# STM32H7P4 register map
File version: 2.0.0
CPU: CM7 r1p2, little endian, MPU, FPU, 4 interrupt priority bits
Registers are 32-bit, read-write, reset 0x0 unless marked. A register's access mark holds for its fields unless they carry their own. Offsets are from the block's base; [hi:lo] are bit positions; {n}, {i} and the like mark numbered series; 'fields as' and 'values as' point back to an identical list.

## HPDMA1 — HPDMA register block
Base 0x52000000
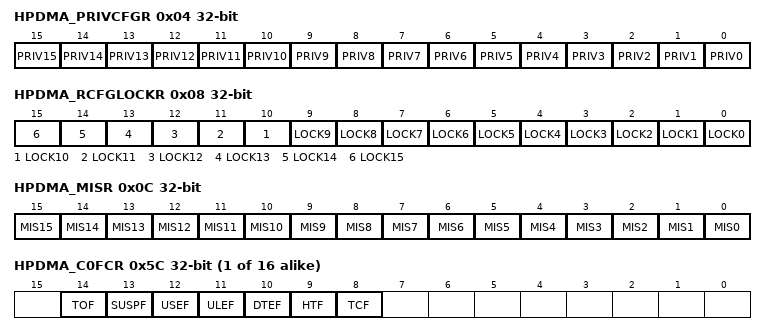
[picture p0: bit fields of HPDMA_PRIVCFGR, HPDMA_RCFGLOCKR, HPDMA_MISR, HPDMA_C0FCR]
0x04 HPDMA_PRIVCFGR — HPDMA privileged configuration register
  [all] fields
    0=Unprivileged; 1=Privileged
  [n] PRIV{n} (n=0..15) — Privileged state of channel x
0x08 HPDMA_RCFGLOCKR — HPDMA configuration lock register
  [all] fields
    0=privilege configuration of the channel x is writable; 1=privilege configuration of the channel x is not writable
  [n] LOCK{n} (n=0..15) — Lock of the configuration of HPDMA_PRIVCFGR.PRIVx until a global HPDMA reset
0x0C HPDMA_MISR ro — HPDMA masked interrupt status register
  [all] fields
    0=No interrupt occurred on channel x; 1=An interrupt occurred on channel x
  [n] MIS{n} (n=0..15) — Masked interrupt status of channel x
{0x50+0x80*i} HPDMA_C{i}LBAR (i=0..15) — HPDMA channel {i} linked-list base address register
  [31:16] LBA — Linked-list base address of HPDMA channel x
{0x5C+0x80*i} HPDMA_C{i}FCR wo (i=0..15) — HPDMA channel {i} flag clear register
  [14] TOF — Trigger overrun flag clear
    0=No effect; 1=Corresponding TOF flag cleared
  [13] SUSPF — Completed suspension flag clear
    0=No effect; 1=Corresponding SUSPF flag cleared
  [12] USEF — User setting error flag clear
    0=No effect; 1=Corresponding USEF flag cleared
  [11] ULEF — Update link transfer error flag clear
    0=No effect; 1=Corresponding ULEF flag cleared
  [10] DTEF — Data transfer error flag clear
    0=No effect; 1=Corresponding DTEF flag cleared
  [9] HTF — Half transfer flag clear
    0=No effect; 1=Corresponding HTF flag cleared
  [8] TCF — Transfer complete flag clear
    0=No effect; 1=Corresponding TCF flag cleared
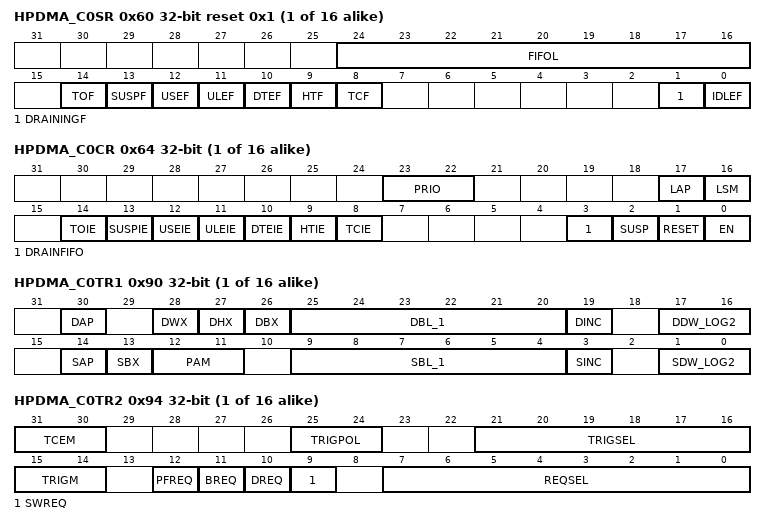
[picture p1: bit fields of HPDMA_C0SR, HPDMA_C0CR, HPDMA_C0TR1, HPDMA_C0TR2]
{0x60+0x80*i} HPDMA_C{i}SR ro reset 0x1 (i=0..15) — HPDMA channel {i} status register
  [24:16] FIFOL — Monitored FIFO level (in bytes)
  [14] TOF — Trigger overrun flag
    0=No trigger overrun event; 1=A trigger overrun event occurred
  [13] SUSPF — Completed suspension flag
    0=No completed suspension event; 1=A completed suspension event occurred
  [12] USEF — User setting error flag
    0=No user setting error event; 1=A user setting error event occurred
  [11] ULEF — Update link transfer error flag
    0=No update link transfer error event; 1=A master bus error event occurred while updating a linked-list register from memory
  [10] DTEF — Data transfer error flag
    0=No data transfer error event; 1=A master bus error event occurred on a data transfer
  [9] HTF — Half transfer flag
    0=No half transfer event; 1=An half transfer event occurred
  [8] TCF — Transfer complete flag
    0=No transfer complete event; 1=A transfer complete event occurred
  [1] DRAININGF — FIFO draining flag
    0=No received order to drain the FIFO or channel FIFO draining completed; 1=On-going channel FIFO draining and channel termination
  [0] IDLEF — Idle flag
    0=Channel not in idle state; 1=Channel in idle state
{0x64+0x80*i} HPDMA_C{i}CR (i=0..15) — HPDMA channel {i} control register
  [23:22] PRIO — Priority level of the channel x HPDMA transfer versus others
    0=Low priority, low weight; 1=Low priority, mid weight; 2=Low priority, high weight; 3=High priority
  [17] LAP — lLnked-list allocated port
    0=Port 0 (AXI) allocated; 1=Port 1 (AHB) allocated
  [16] LSM — Link step mode
    0=Channel executed for the full linked-list and completed at the end of the last LLI (HPDMA_CxLLR = 0). The 16 low-significant bits of the link address are null (LA[15:0] = 0) and all the update bits are null (UT1 = UB1 = UT2 = USA = UDA = ULL = 0 and; 1=Channel executed once for the current LLI
  [14] TOIE — Trigger overrun interrupt enable
    0=Interrupt disabled; 1=Interrupt enabled
  [13] SUSPIE — cCmpleted suspension interrupt enable
    0=Interrupt disabled; 1=Interrupt enabled
  [12] USEIE — User setting error interrupt enable
    0=Interrupt disabled; 1=Interrupt enabled
  [11] ULEIE — Update link transfer error interrupt enable
    0=Interrupt disabled; 1=Interrupt enabled
  [10] DTEIE — Data transfer error interrupt enable
    0=Interrupt disabled; 1=Interrupt enabled
  [9] HTIE — Half transfer complete interrupt enable
    0=Interrupt disabled; 1=Interrupt enabled
  [8] TCIE — Transfer complete interrupt enable
    0=Interrupt disabled; 1=Interrupt enabled
  [3] DRAINFIFO wo — Empty FIFO
    0=Write: no action; 1=Write: drain FIFO after having suspended the channel
  [2] SUSP — Suspend
    0=Write: resume channel, read: channel not suspended; 1=Write: suspend channel, read: channel suspended
  [1] RESET wo
    0=No channel reset; 1=Channel reset
  [0] EN — Enable
    0=Write: ignored, read: channel disabled; 1=Write: enable channel, read: channel enabled
{0x90+0x80*i} HPDMA_C{i}TR1 (i=0..15) — HPDMA channel {i} transfer register 1
  [30] DAP — Destination allocated port
    0=Port 0 (AXI) allocated; 1=Port 1 (AHB) allocated
  [28] DWX — Destination word exchange
    0=No word-based exchanged within double-word; 1=The two consecutive (post PAM) words are exchanged in each destination double-word
  [27] DHX — Destination half-word exchange
    0=No half-word-based exchanged within word; 1=The two consecutive (post PAM) half-words are exchanged in each destination word
  [26] DBX — Destination byte exchange
    0=No byte-based exchange within half-word; 1=The two consecutive (post PAM) bytes are exchanged in each destination half-word
  [25:20] DBL_1 — Destination burst length minus 1, between 0 and 63
  [19] DINC — Destination incrementing burst
    0=Fixed burst; 1=Contiguously incremented burst
  [17:16] DDW_LOG2 — Binary logarithm of the destination data width of a burst, in bytes
    0=Byte; 1=Half-word (2 bytes); 2=Word (4 bytes); 3=If DAP = 0 (AXI), double-word (8 bytes)
  [14] SAP — Source allocated port
    0=Port 0 (AXI) allocated; 1=Port 1 (AHB) allocated
  [13] SBX — Source byte exchange within the unaligned half-word of each source word
    0=No byte-based exchange within the unaligned half-word of each source word; 1=The two consecutive bytes within the unaligned half-word of each source word
  [12:11] PAM — Padding/alignment mode
    0=B_0x0_PAM_1 (Source data is transferred as right aligned, padded with 0s up to the destination data width); 1=B_0x1_PAM_1 (Source data is transferred as right aligned, sign extended up to the destination data width); 2=B_0x2_PAM_1 (Successive source data are FIFO queued and packed at the destination data width, in a left (LSB) to right (MSB) order (named little endian), before a destination transfer); 3=B_0x3_PAM_1 (Successive source data are FIFO queued and packed at the destination data width, in a left (LSB) to right (MSB) order (named little endian), before a destination transfer)
  [9:4] SBL_1 — Source burst length minus 1, between 0 and 63
  [3] SINC — Source incrementing burst
    0=Fixed burst; 1=Contiguously incremented burst
  [1:0] SDW_LOG2 — Binary logarithm of the source data width of a burst in bytes
    0=Byte; 1=Half-word (2 bytes); 2=Word (4 bytes); 3=If SAP = 0 (AXI), double-word (8 bytes)
{0x94+0x80*i} HPDMA_C{i}TR2 (i=0..15) — HPDMA channel {i} transfer register 2
  [31:30] TCEM — Transfer complete event mode
    0=At block level (when HPDMA_CxBR1.BNDT[15:0] = 0): The complete (and the half) transfer event is generated at the (respectively half of the) end of a block; 1=Channel x = 0 to 11, same as 00; channel x = 12 to 15, at 2D/repeated block level; 2=At LLI level: The complete transfer event is generated at the end of the LLI transfer, including the update of the LLI if any. The half transfer event is generated at the half of the LLI data transfer (the LLI data transfer being a block transfer or a 2D/repeated block transfer for channel x = 12 to 15), if any data transfer.; 3=At channel level: The complete transfer event is generated at the end of the last LLI transfer. The half transfer event is generated at the half of the data transfer of the last LLI. The last LLI updates the link address HPDMA_CxLLR.LA[15:2] to zero and clears all the HPDMA_CxLLR update bits (UT1, UT2, UB1, USA, UDA and ULL, plus UT3 and UB2 if present). If the channel transfer is continuous/infinite, no event is generated.
  [25:24] TRIGPOL — Trigger event polarity
    0=No trigger (masked trigger event); 1=Trigger on the rising edge; 2=Trigger on the falling edge; 3=Same as 00
  [21:16] TRIGSEL — Trigger event input selection
  [15:14] TRIGM — Trigger mode
    0=at block level: the first burst read of each block transfer is conditioned by one hit trigger (channel x = 12 to 15, for each block if a 2D/repeated block is configured with HPDMA_CxBR1.BRC[10:0] different to 0); 1=channel x = 0 to 11, same as 00; channel x = 12 to 15, at 2D/repeated block level, the first burst read of a 2D/repeated block transfer is conditioned by one hit trigger; 2=at link level: a LLI link transfer is conditioned by one hit trigger. The LLI data transfer; 3=at programmed burst level: If SWREQ = 1, each programmed burst read is conditioned by one hit trigger. If SWREQ = 0, each programmed burst that is requested by the selected peripheral, is conditioned by one hit trigger.
  [12] PFREQ — Hardware request in peripheral flow control mode
    0=The selected hardware request is driven by a peripheral with a hardware request/acknowledge protocol in HPDMA control mode. The HPDMA is programmed with HPDMA_CxCBR1.BNDT[15:0] and this is internally used by the hardware for the block transfer completion.; 1=The selected hardware request is driven by a peripheral with a hardware request/acknowledge protocol in peripheral control mode. The HPDMA block transfer can be early completed by the peripheral itself (see Section26.3.5 for more details).
  [11] BREQ — Block hardware request
    0=The selected hardware request is driven by a peripheral with a hardware request/acknowledge protocol at a burst level; 1=The selected hardware request is driven by a peripheral with a hardware request/acknowledge protocol at a block level (see Section26.3.4)
  [10] DREQ — Destination hardware request
    0=Selected hardware request driven by a source peripheral (request signal taken into account by the HPDMA transfer scheduler over the source/read port); 1=Selected hardware request driven by a destination peripheral (request signal taken into account by the HPDMA transfer scheduler over the destination/write port)
  [9] SWREQ — Software request
    0=No software request. The selected hardware request REQSEL[7:0] is taken into account.; 1=Software request for a memory-to-memory transfer. The default selected hardware request as per REQSEL[7:0] is ignored.
  [7:0] REQSEL — Hardware request selection
{0x98+0x80*i} HPDMA_C{i}BR1 (i=0..11) — HPDMA channel {i} block register 1
  [15:0] BNDT — Block number of data bytes to transfer from the source
{0x9C+0x80*i} HPDMA_C{i}SAR (i=0..15) — HPDMA channel {i} source address register
  [31:0] SA — Source address
{0xA0+0x80*i} HPDMA_C{i}DAR (i=0..15) — HPDMA channel {i} destination address register
  [31:0] DA — destination address
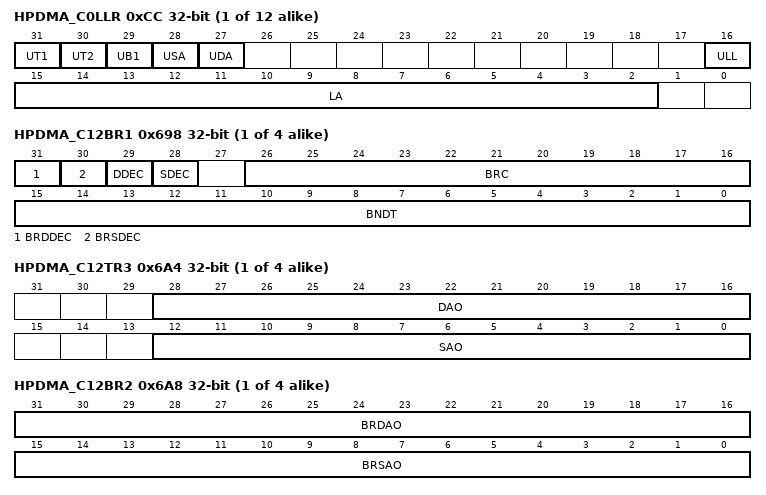
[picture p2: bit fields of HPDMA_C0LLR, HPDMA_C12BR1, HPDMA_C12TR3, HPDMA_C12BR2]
{0xCC+0x80*i} HPDMA_C{i}LLR (i=0..11) — HPDMA channel {i} linked-list address register
  [31] UT1 — Update HPDMA_CxTR1 from memory
    0=No HPDMA_CxTR1 update; 1=HPDMA_CxTR1 update
  [30] UT2 — Update HPDMA_CxTR2 from memory
    0=No HPDMA_CxTR2 update; 1=HPDMA_CxTR2 update
  [29] UB1 — Update HPDMA_CxBR1 from memory
    0=No HPDMA_CxBR1 update from memory (HPDMA_CxBR1.BNDT[15:0] restored if any link transfer); 1=HPDMA_CxBR1 update
  [28] USA — Update HPDMA_CxSAR from memory
    0=No HPDMA_CxSAR update; 1=HPDMA_CxSAR update
  [27] UDA — Update HPDMA_CxDAR register from memory
    0=No HPDMA_CxDAR update; 1=HPDMA_CxDAR update
  [16] ULL — Update HPDMA_CxLLR register from memory
    0=No HPDMA_CxLLR update; 1=HPDMA_CxLLR update
  [15:2] LA — Pointer (16-bit low-significant address) to the next linked-list data structure
{0x98+0x80*i} HPDMA_C{i}BR1 (i=12..15) — HPDMA channel {i} alternate block register 1
  [31] BRDDEC — Block repeat destination address decrement
    0=At the end of a block transfer, the HPDMA_CxDAR register is updated by adding the programmed offset HPDMA_CxBR2.BRDAO to the current HPDMA_CxDAR value (current destination address); 1=At the end of a block transfer, the HPDMA_CxDAR register is updated by subtracting the programmed offset HPDMA_CxBR2.BRDAO from the current HPDMA_CxDAR value (current destination address)
  [30] BRSDEC — Block repeat source address decrement
    0=At the end of a block transfer, the HPDMA_CxSAR register is updated by adding the programmed offset HPDMA_CxBR2.BRSAO to the current HPDMA_CxSAR value (current source address); 1=At the end of a block transfer, the HPDMA_CxSAR register is updated by subtracting the programmed offset HPDMA_CxBR2.BRSAO from the current HPDMA_CxSAR value (current source address)
  [29] DDEC — destination address decrement
    0=At the end of a programmed burst transfer to the destination, the HPDMA_CxDAR register is updated by adding the programmed offset HPDMA_CxTR3.DAO to the current HPDMA_CxDAR value (current destination address); 1=At the end of a programmed burst transfer to the destination, the HPDMA_CxDAR register is updated by subtracting the programmed offset HPDMA_CxTR3.DAO to the current HPDMA_CxDAR value (current destination address)
  [28] SDEC — source address decrement
    0=At the end of a programmed burst transfer from the source, the HPDMA_CxSAR register is updated by adding the programmed offset HPDMA_CxTR3.SAO to the current HPDMA_CxSAR value (current source address); 1=At the end of a programmed burst transfer from the source, the HPDMA_CxSAR register is updated by subtracting the programmed offset HPDMA_CxTR3.SAO to the current HPDMA_CxSAR value (current source address)
  [26:16] BRC — Block repeat counter
  [15:0] BNDT — Block number of data bytes to transfer from the source
{0xA4+0x80*i} HPDMA_C{i}TR3 (i=12..15) — HPDMA channel {i} transfer register 3
  [28:16] DAO — Destination address offset increment
  [12:0] SAO — Source address offset increment
{0xA8+0x80*i} HPDMA_C{i}BR2 (i=12..15) — HPDMA channel {i} block register 2
  [31:16] BRDAO — Block repeated destination address offset
  [15:0] BRSAO — Block repeated source address offset
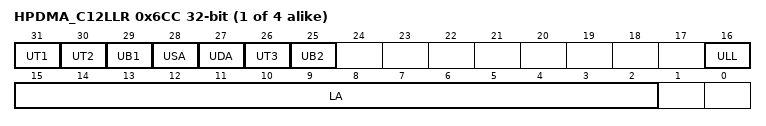
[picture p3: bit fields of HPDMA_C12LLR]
{0xCC+0x80*i} HPDMA_C{i}LLR (i=12..15) — HPDMA channel {i} alternate linked-list address register
  [31] UT1 — Update HPDMA_CxTR1 from memory
    0=No HPDMA_CxTR1 update; 1=HPDMA_CxTR1 update
  [30] UT2 — Update HPDMA_CxTR2 from memory
    0=No HPDMA_CxTR2 update; 1=HPDMA_CxTR2 update
  [29] UB1 — Update HPDMA_CxBR1 from memory
    values as HPDMA_C0LLR.UB1
  [28] USA — Update HPDMA_CxSAR from memory
    0=No HPDMA_CxSAR update; 1=HPDMA_CxSAR update
  [27] UDA — Update HPDMA_CxDAR register from memory
    0=No HPDMA_CxDAR update; 1=HPDMA_CxDAR update
  [26] UT3 — Update HPDMA_CxTR3 from memory
    0=No HPDMA_CxTR3 update; 1=HPDMA_CxTR3 update
  [25] UB2 — Update HPDMA_CxBR2 from memory
    0=No HPDMA_CxBR2 update; 1=HPDMA_CxBR2 update
  [16] ULL — Update HPDMA_CxLLR register from memory
    0=No HPDMA_CxLLR update; 1=HPDMA_CxLLR update
  [15:2] LA — Pointer (16-bit low-significant address) to the next linked-list data structure
